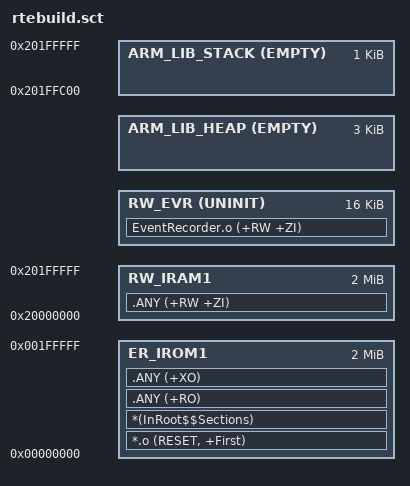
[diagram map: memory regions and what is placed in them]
; *************************************************************
; *** Scatter-Loading Description File generated by uVision ***
; *************************************************************

LR_IROM1 0x00000000 0x00200000  {    ; load region size_region
  ER_IROM1 0x00000000 0x00200000  {  ; load address = execution address
   *.o (RESET, +First)
   *(InRoot$$Sections)
   .ANY (+RO)
   .ANY (+XO)
  }
  RW_IRAM1 0x20000000 0x00200000  {  ; RW data
   .ANY (+RW +ZI)
  }
  RW_EVR +0 UNINIT 0x00004000 {
    EventRecorder.o (+RW +ZI)
  }
  ARM_LIB_HEAP  (AlignExpr(+0, 8)) EMPTY  0xC00  {   ; Reserve empty region for heap
  }
  ARM_LIB_STACK 0x20200000 EMPTY -0x400 {   ; Reserve empty region for stack
  }
}

